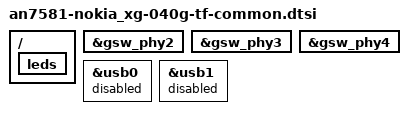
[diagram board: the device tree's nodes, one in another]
// SPDX-License-Identifier: GPL-2.0-only OR MIT

#include "an7581-nokia_xg-040g-md-common.dtsi"

/ {
	/* The TF panel exposes power, PON, LOS, and network status LEDs. */
	leds {
		/delete-node/ led-4;
		/delete-node/ led-5;
	};

	/delete-node/ regulator-usb-5v;
	/delete-node/ usb-power;
};

/* The TF internal Gigabit PHY uses phylib polling. */
&gsw_phy2 {
	/delete-property/ interrupts;
};

&gsw_phy3 {
	/delete-property/ interrupts;
};

&gsw_phy4 {
	/delete-property/ interrupts;
};

&usb0 {
	status = "disabled";

	/delete-property/ vusb33-supply;
	/delete-node/ port@1;
};

&usb1 {
	status = "disabled";

	/delete-property/ mediatek,u3p-dis-msk;
	/delete-property/ phys;
	/delete-property/ vusb33-supply;
	/delete-node/ port@1;
};
